# M3351 register map
File version: 1.0
Registers are 32-bit, read-write, reset 0x0 unless marked. A register's access mark holds for its fields unless they carry their own. Offsets are from the block's base; [hi:lo] are bit positions; {n}, {i} and the like mark numbered series; 'fields as' and 'values as' point back to an identical list.

## PDMA0 — PDMA Register Map
Base 0x40008000
Same registers: PDMA0_NS 0x50008000
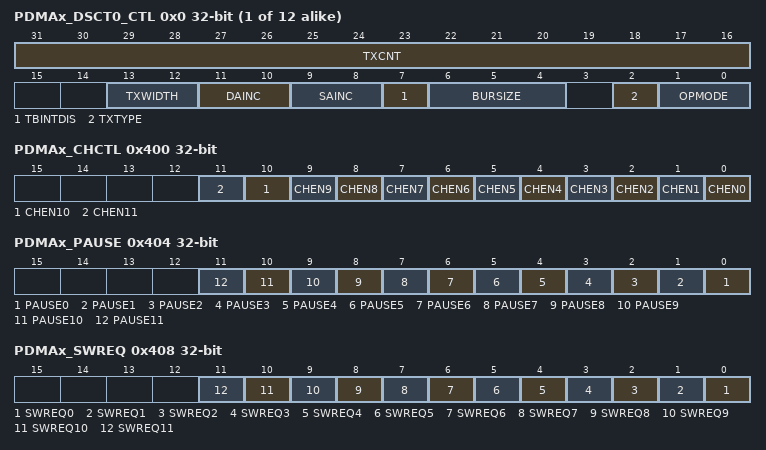
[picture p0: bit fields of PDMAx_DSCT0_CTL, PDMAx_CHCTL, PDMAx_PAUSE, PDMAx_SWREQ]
{0x0+0x10*i} PDMAx_DSCT{i}_CTL reset not defined (i=0..11) — Descriptor Table Control Register of PDMA Channel n
  [31:16] TXCNT — Transfer Count. The TXCNT represents the required number of PDMA transfer, the real transfer count is (TXCNT + 1); The maximum transfer count is 65536, every transfer may be byte, half-word or word that is dependent on TXWIDTH field. Note: When PDMA finishes each transfer data, this field will be decreased immediately.
  [13:12] TXWIDTH — Transfer Width Selection. This field is used for transfer width. Note: The PDMA transfer source address (PDMA_DSCTn_SA) and PDMA transfer destination address (PDMA_DSCTn_DA) should be alignment under the TXWIDTH selection
    0=One byte (8 bit) is transferred for every operation; 1=One half-word (16 bit) is transferred for every operation; 2=One word (32-bit) is transferred for every operation
  [11:10] DAINC — Destination Address Increment. This field is used to set the destination address increment size. Note: The fixed address function does not support in memory to memory transfer type.
    3=No increment (fixed address)
  [9:8] SAINC — Source Address Increment. This field is used to set the source address increment size. Note: The fixed address function does not support in memory to memory transfer type.
    3=No increment (fixed address)
  [7] TBINTDIS — Table Interrupt Disable Bit. This field can be used to decide whether to enable table interrupt or not. If the TBINTDIS bit is enabled it will not generates TDIFn(PDMA_TDSTS[15:0]) when PDMA controller finishes transfer task. Note: This function only for Scatter-gather mode.
    0=Table interrupt Enabled; 1=Table interrupt Disabled
  [6:4] BURSIZE — Burst Size. This field is used for peripheral to determine the burst size or used for determine the re-arbitration size. Note: This field is only useful in burst transfer type.
    0=128 Transfers; 1=64 Transfers; 2=32 Transfers; 3=16 Transfers; 4=8 Transfers; 5=4 Transfers; 6=2 Transfers; 7=1 Transfers
  [2] TXTYPE — Transfer Type
    0=Burst transfer type; 1=Single transfer type
  [1:0] OPMODE — PDMA Operation Mode Selection. Note: Before filling new transfer task in the Descriptor Table, user must check the PDMA_INTSTS[1] to make sure the current task is complete.
    0=Idle state: Channel is stopped or this table is complete, when PDMA finish channel table task, OPMODE will be cleared to idle state automatically; 1=Basic mode: The descriptor table only has one task. When this task is finished, the PDMA_INTSTS[1] will be asserted; 2=Scatter-gather mode: When operating in this mode, user must give the next descriptor table address in PDMA_DSCTn_NEXT register; PDMA controller will ignore this task, then load the next task to execute
{0x4+0x10*i} PDMAx_DSCT{i}_SA reset not defined (i=0..11) — Source Address Register of PDMA Channel n
  [31:0] SA — PDMA Transfer Source Address. This field indicates a 32-bit source address of PDMA controller.
{0x8+0x10*i} PDMAx_DSCT{i}_DA reset not defined (i=0..11) — Destination Address Register of PDMA Channel n
  [31:0] DA — PDMA Transfer Destination Address. This field indicates a 32-bit destination address of PDMA controller.
{0xC+0x10*i} PDMAx_DSCT{i}_NEXT reset not defined (i=0..11) — Next Scatter-gather Descriptor Table Address of PDMA Channel n
  [31:0] NEXT — PDMA Next Descriptor Table. This field indicates the next descriptor table address in system memory. When operating in Scatter-gather mode, the last two bits NEXT[1:0] will become reserved, and indicate the first next address of system memory. Note 1: The descriptor table address must be word boundary. Note 2: Before filling transfer task in the descriptor table, user must check if the descriptor table is complete.
{0x100+4i} PDMAx_CURSCAT{i} ro reset not defined (i=0..11) — Current Scatter-gather Descriptor Table Address of PDMA Channel n
  [31:0] CURADDR — PDMA Current Description Address (Read Only). This field indicates a 32-bit current external description address of PDMA controller. Note: This field is read only and used for Scatter-gather mode only to indicate the current external description address.
0x400 PDMAx_CHCTL — PDMA Channel Control Register
  [all] fields
    0=PDMA channel [n] Disabled; 1=PDMA channel [n] Enabled
  [n] CHEN{n} (n=0..11) — PDMA Channel Enable Bits. Set this bit to 1 to enable PDMAn operation. Channel cannot be active if it is not set as enabled. Note: Setting the corresponding bit of PDMA_PAUSE or PDMA_CHRST register will also clear this bit.
0x404 PDMAx_PAUSE wo — PDMA Transfer Pause Control Register
  [all] fields
    0=No effect; 1=Pause PDMA channel n transfer
  [n] PAUSE{n} (n=0..11) — PDMA Channel n Transfer Pause Control (Write Only)
0x408 PDMAx_SWREQ wo — PDMA Software Request Register
  [all] fields
    0=No effect; 1=Generate a software request
  [n] SWREQ{n} (n=0..11) — PDMA Software Request (Write Only). Set this bit to 1 to generate a software request to PDMA [n]. Note 1: User can read PDMA_TRGSTS register to know which channel is on active. Active flag may be triggered by software request or peripheral request. Note 2: If user does not enable corresponding PDMA channel, the software request will be ignored.
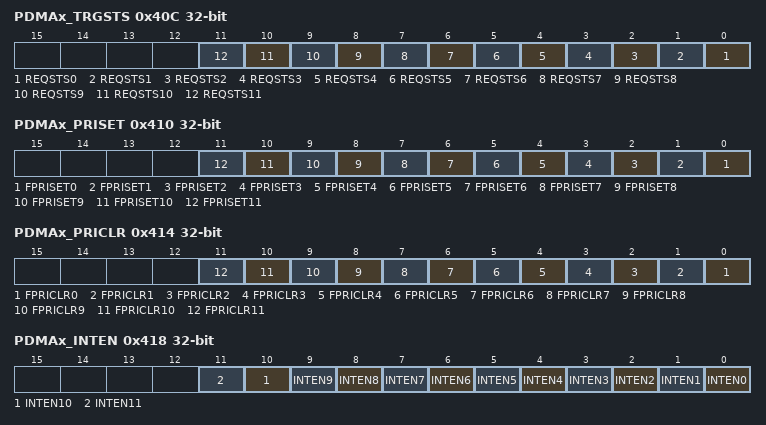
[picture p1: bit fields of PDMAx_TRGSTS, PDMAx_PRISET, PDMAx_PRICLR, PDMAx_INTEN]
0x40C PDMAx_TRGSTS ro — PDMA Channel Request Status Register
  [all] fields
    0=PDMA Channel n has no request; 1=PDMA Channel n has a request
  [n] REQSTS{n} (n=0..11) — PDMA Channel Request Status (Read Only). This flag indicates whether channel[n] have a request or not, no matter request from software or peripheral. When PDMA controller finishes channel transfer, this bit will be cleared automatically. Note: If user pauses or resets each PDMA transfer by setting PDMA_PAUSE or PDMA_CHRST register respectively, this bit will be cleared automatically after finishing the current transfer.
0x410 PDMAx_PRISET — PDMA Fixed Priority Setting Register
  [all] fields
    0=No effect. Corresponding PDMA channel is round-robin priority; 1=Set PDMA channel [n] to fixed priority channel. Corresponding PDMA channel is fixed priority
  [n] FPRISET{n} (n=0..11) — PDMA Fixed Priority Setting. Set this bit to 1 to enable fixed priority level. Write Operation: Note: This field is only set to fixed priority. To clear fixed priority, use PDMA_PRICLR register.
0x414 PDMAx_PRICLR wo — PDMA Fixed Priority Clear Register
  [all] fields
    0=No effect; 1=Clear PDMA channel [n] fixed priority setting
  [n] FPRICLR{n} (n=0..11) — PDMA Fixed Priority Clear Bits (Write Only). Set this bit to 1 to clear fixed priority level. Note: User can read PDMA_PRISET register to know the channel priority.
0x418 PDMAx_INTEN — PDMA Interrupt Enable Register
  [all] fields
    0=PDMA channel n interrupt Disabled; 1=PDMA channel n interrupt Enabled
  [n] INTEN{n} (n=0..11) — PDMA Interrupt Enable Bits. This field is used to enable PDMA channel[n] interrupt. Note: The interrupt flag is time-out, abort, transfer done and align.
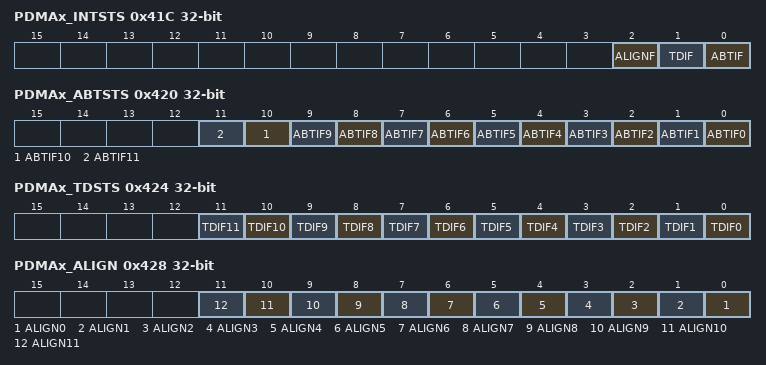
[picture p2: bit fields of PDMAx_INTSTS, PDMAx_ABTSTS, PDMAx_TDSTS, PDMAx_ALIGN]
0x41C PDMAx_INTSTS — PDMA Interrupt Status Register
  [2] ALIGNF — Transfer Alignment Interrupt Flag (Read Only)
    0=PDMA channel source address and destination address both follow transfer width setting; 1=PDMA channel source address or destination address is not follow transfer width setting
  [1] TDIF — Transfer Done Interrupt Flag (Read Only). This bit indicates that PDMA controller has finished transmission; User can read PDMA_TDSTS register to indicate which channel finished transfer.
    0=Not finished yet; 1=PDMA channel has finished transmission
  [0] ABTIF — PDMA Read/Write Target Abort Interrupt Flag (Read Only). This bit indicates that PDMA has target abort error; Software can read PDMA_ABTSTS register to find which channel has target abort error.
    0=No AHB bus ERROR response received; 1=AHB bus ERROR response received
0x420 PDMAx_ABTSTS — PDMA Channel Read/Write Target Abort Flag Register
  [all] fields
    0=No AHB bus ERROR response received when channel n transfer; 1=AHB bus ERROR response received when channel n transfer
  [n] ABTIF{n} (n=0..11) — PDMA Read/Write Target Abort Interrupt Status Flag. This bit indicates which PDMA controller has target abort error. Note 1: If channel n target abort, REQSRCn should set0 to disable peripheral request. Note 2: User can write 1 to clear this bit.
0x424 PDMAx_TDSTS — PDMA Channel Transfer Done Flag Register
  [all] fields
    0=PDMA channel transfer has not finished; 1=PDMA channel has finished transmission
  [n] TDIF{n} (n=0..11) — Transfer Done Flag. This bit indicates whether PDMA controller channel transfer has been finished or not. Note: User can write 1 to clear these bits.
0x428 PDMAx_ALIGN — PDMA Transfer Alignment Status Register
  [all] fields
    values as PDMAx_INTSTS.ALIGNF
  [n] ALIGN{n} (n=0..11) — Transfer Alignment Flag. This bit indicates whether source and destination address both follow transfer width setting. Note: User can write 1 to clear these bits.
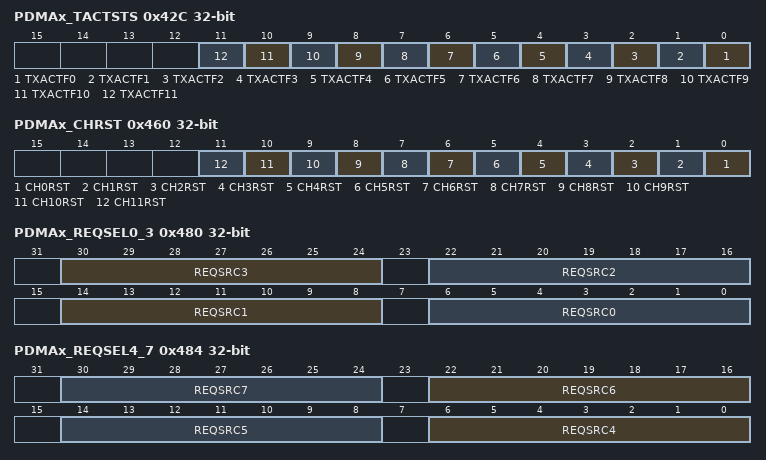
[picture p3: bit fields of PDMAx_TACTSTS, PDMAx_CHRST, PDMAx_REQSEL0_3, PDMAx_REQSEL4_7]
0x42C PDMAx_TACTSTS ro — PDMA Transfer Active Flag Register
  [all] fields
    0=PDMA channel is finished; 1=PDMA channel is active
  [n] TXACTF{n} (n=0..11) — Transfer on Active Flag (Read Only). This bit indicates which PDMA channel is in active.
0x460 PDMAx_CHRST — PDMA Channel Reset Register
  [all] fields
    0=Corresponding channel n is not reset; 1=Corresponding channel n is reset
  [n] CH{n}RST (n=0..11) — Channel n Reset
0x480 PDMAx_REQSEL0_3 — PDMA Request Source Select Register 0
  [30:24] REQSRC3 — Channel 3 Request Source Selection. This filed defines which peripheral is connected to PDMA channel 3. User can configure the peripheral setting by REQSRC3. Note: The channel configuration is the same as REQSRC0 field. Please refer to the explanation of REQSRC0.
  [22:16] REQSRC2 — Channel 2 Request Source Selection. This filed defines which peripheral is connected to PDMA channel 2. User can configure the peripheral setting by REQSRC2. Note: The channel configuration is the same as REQSRC0 field. Please refer to the explanation of REQSRC0.
  [14:8] REQSRC1 — Channel 1 Request Source Selection. This filed defines which peripheral is connected to PDMA channel 1. User can configure the peripheral setting by REQSRC1. Note: The channel configuration is the same as REQSRC0 field. Please refer to the explanation of REQSRC0.
  [6:0] REQSRC0 — Channel 0 Request Source Selection. This filed defines which peripheral is connected to PDMA channel 0. User can configure the peripheral by setting REQSRC0. Note 1: A peripheral cannot be assigned to two channels at the same time. Note 2: This field is useless when transfer between memory and memory.
    0=Disable PDMA peripheral request; 4=Channel connects to UART0_TX; 5=Channel connects to UART0_RX; 6=Channel connects to UART1_TX; 7=Channel connects to UART1_RX; 8=Channel connects to UART2_TX; 9=Channel connects to UART2_RX; 10=Channel connects to UART3_TX; 11=Channel connects to UART3_RX; 12=Channel connects to UART4_TX; 13=Channel connects to UART4_RX; 14=Channel connects to UART5_TX; 15=Channel connects to UART5_RX; 16=Channel connects to USCI0_TX; 17=Channel connects to USCI0_RX; 18=Channel connects to USCI1_TX; 19=Channel connects to USCI1_RX; 20=Channel connects to QSPI0_TX; 21=Channel connects to QSPI0_RX; 22=Channel connects to SPI0_TX; 23=Channel connects to SPI0_RX; 24=Channel connects to SPI1_TX; 25=Channel connects to SPI1_RX; 30=Channel connects to ACMP0_INT; 31=Channel connects to ACMP1_INT; 32=Channel connects to PWM0_P1_RX; 33=Channel connects to PWM0_P2_RX; 34=Channel connects to PWM0_P3_RX; 35=Channel connects to PWM1_P1_RX; 36=Channel connects to PWM1_P2_RX; 37=Channel connects to PWM1_P3_RX; 38=Channel connects to I2C0_TX; 39=Channel connects to I2C0_RX; 40=Channel connects to I2C1_TX; 41=Channel connects to I2C1_RX; 42=Channel connects to I2C2_TX; 43=Channel connects to I2C2_RX; {v}=Channel connects to TMR{v-46} (v=46..49); 50=Channel connects to DAC0_TX; {v}=Channel connects to LLSI{v-52}_TX (v=52..61); 62=Channel connects to ELLSI0_TX; 63=Channel connects to ELLSI1_TX; 64=Channel connects to EADC0_RX; 65=Channel connects to EADC1_RX; 66=Channel connects to UART6_TX; 67=Channel connects to UART6_RX; 68=Channel connects to UART7_TX; 69=Channel connects to UART7_RX; 76=Channel connects to PWM0_CH0_TX; 77=Channel connects to PWM0_CH2_TX; 78=Channel connects to PWM0_CH4_TX; 79=Channel connects to PWM1_CH0_TX; 80=Channel connects to PWM1_CH2_TX; 81=Channel connects to PWM1_CH4_TX; {v}=Channel connects to EINT{v-82} (v=82..89); 90=Channel connects to UART8_TX; 91=Channel connects to UART8_RX; 92=Channel connects to UART9_TX; 93=Channel connects to UART9_RX; 94=Channel connects to I3C0_TX; 95=Channel connects to I3C0_RX
0x484 PDMAx_REQSEL4_7 — PDMA Request Source Select Register 1
  [8n-26:8n-32] REQSRC{n} (n=4..7) — Channel {n} Request Source Selection. This filed defines which peripheral is connected to PDMA channel {n}. User can configure the peripheral setting by REQSRC{n}. Note: The channel configuration is the same as REQSRC0 field. Please refer to the explanation of REQSRC0.
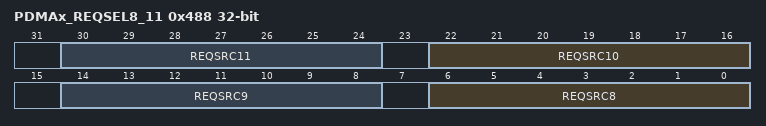
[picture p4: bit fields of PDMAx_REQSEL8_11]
0x488 PDMAx_REQSEL8_11 — PDMA Request Source Select Register 2
  [8n-58:8n-64] REQSRC{n} (n=8..11) — Channel {n} Request Source Selection. This filed defines which peripheral is connected to PDMA channel {n}. User can configure the peripheral setting by REQSRC{n}. Note: The channel configuration is the same as REQSRC0 field. Please refer to the explanation of REQSRC0.
